AUTOSAR XML (schema 4-0-3)
standard types defined: uint8, Boolean, UInt16, UInt32, UInt8
package /AUTOSAR_Platform/DataConstrs
  range DC_Boolean: raw 0..1
  range DC_UInt16: raw 0..65535
  range DC_UInt8: raw 0..255
package /PATAC/Facility/DataTypes/Implementation
  compu method COMPU_Boolean: 0=FALSE, 1=TRUE
  unit NoUnit: factor-si-to-unit=1, offset-si-to-unit=0
package /PATAC/MSM/ComponentTypes
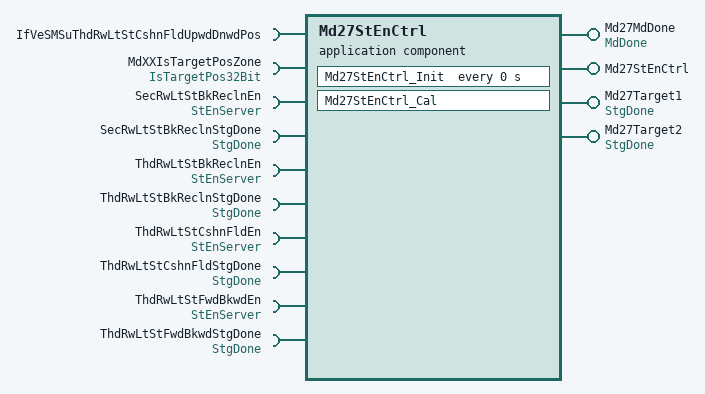
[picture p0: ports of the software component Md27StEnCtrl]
  application sw component type Md27StEnCtrl
    4 x provide port:
      Md27MdDone: nonqueued-sender-com-spec{data-element=MdDone/Val, init-value=0}, provided-interface=MdDone
      Md27StEnCtrl: server-com-spec{operation=Cal, queue-length=1}, provided-interface=Md27StEnCtrl
      Md27Target1: nonqueued-sender-com-spec{data-element=StgDone/Val, init-value=0}, provided-interface=StgDone
      Md27Target2: nonqueued-sender-com-spec{data-element=StgDone/Val, init-value=0}, provided-interface=StgDone
    10 x require port:
      IfVeSMSuThdRwLtStCshnFldUpwdDnwdPos: nonqueued-receiver-com-spec{data-element=IfVeSMSuThdRwLtStCshnFldUpwdDnwdPos/Val, filter=data-filter-type=ALWAYS, init-value=0}, required-interface=IfVeSMSuThdRwLtStCshnFldUpwdDnwdPos
      MdXXIsTargetPosZone: nonqueued-receiver-com-spec{data-element=IsTargetPos32Bit/Val, filter=data-filter-type=ALWAYS, init-value=0}, required-interface=IsTargetPos32Bit
      SecRwLtStBkReclnEn: required-com-specs=[Clear, Get, Set], required-interface=StEnServer
      SecRwLtStBkReclnStgDone: nonqueued-receiver-com-spec{data-element=StgDone/Val, filter=data-filter-type=ALWAYS, init-value=0}, required-interface=StgDone
      ThdRwLtStBkReclnEn: required-com-specs=[Clear, Get, Set], required-interface=StEnServer
      ThdRwLtStBkReclnStgDone: nonqueued-receiver-com-spec{data-element=StgDone/Val, filter=data-filter-type=ALWAYS, init-value=0}, required-interface=StgDone
      ThdRwLtStCshnFldEn: required-com-specs=[Clear, Get, Set], required-interface=StEnServer
      ThdRwLtStCshnFldStgDone: nonqueued-receiver-com-spec{data-element=StgDone/Val, filter=data-filter-type=ALWAYS, init-value=0}, required-interface=StgDone
      ThdRwLtStFwdBkwdEn: required-com-specs=[Clear, Get, Set], required-interface=StEnServer
      ThdRwLtStFwdBkwdStgDone: nonqueued-receiver-com-spec{data-element=StgDone/Val, filter=data-filter-type=ALWAYS, init-value=0}, required-interface=StgDone
    behavior Md27StEnCtrl_InternalBehavior
      operation invoked event OIT_Md27StEnCtrl_Cal_Md27StEnCtrl_Cal: start-on-event=Md27StEnCtrl_Cal, operation=Md27StEnCtrl.Cal
      timing event Md27StEnCtrl_InitEvent: start-on-event=Md27StEnCtrl_Init, period=0
      runnable Md27StEnCtrl_Cal
        data-receive-point-by-arguments:
          6 x access:
            REC_IfVeSMSuThdRwLtStCshnFldUpwdDnwdPos_Val: accessed-variable=IfVeSMSuThdRwLtStCshnFldUpwdDnwdPos.Val
            REC_MdXXIsTargetPosZone_Val: accessed-variable=MdXXIsTargetPosZone.Val
            REC_SecRwLtStBkReclnStgDone_Val: accessed-variable=SecRwLtStBkReclnStgDone.Val
            REC_ThdRwLtStBkReclnStgDone_Val: accessed-variable=ThdRwLtStBkReclnStgDone.Val
            REC_ThdRwLtStCshnFldStgDone_Val: accessed-variable=ThdRwLtStCshnFldStgDone.Val
            REC_ThdRwLtStFwdBkwdStgDone_Val: accessed-variable=ThdRwLtStFwdBkwdStgDone.Val
        data-send-points:
          access SEND_Md27MdDone_Val: accessed-variable=Md27MdDone.Val
          access SEND_Md27Target1_Val: accessed-variable=Md27Target1.Val
          access SEND_Md27Target2_Val: accessed-variable=Md27Target2.Val
        8 x sync call, all with timeout=0:
          SC_SecRwLtStBkReclnEn_Clear: operation=SecRwLtStBkReclnEn.Clear
          SC_SecRwLtStBkReclnEn_Set: operation=SecRwLtStBkReclnEn.Set
          SC_ThdRwLtStBkReclnEn_Clear: operation=ThdRwLtStBkReclnEn.Clear
          SC_ThdRwLtStBkReclnEn_Set: operation=ThdRwLtStBkReclnEn.Set
          SC_ThdRwLtStCshnFldEn_Clear: operation=ThdRwLtStCshnFldEn.Clear
          SC_ThdRwLtStCshnFldEn_Set: operation=ThdRwLtStCshnFldEn.Set
          SC_ThdRwLtStFwdBkwdEn_Clear: operation=ThdRwLtStFwdBkwdEn.Clear
          SC_ThdRwLtStFwdBkwdEn_Set: operation=ThdRwLtStFwdBkwdEn.Set
      runnable Md27StEnCtrl_Init
  swc implementation Md27StEnCtrl_Implementation: behavior=Md27StEnCtrl_InternalBehavior
    code-descriptors:
      code Default: artifact-descriptors=autosar-engineering-object={short-label=Default, category=SWSRC}
package /PATAC/MSM/ModeAdjust/Interfaces
  sender receiver interface IfVeSMSuThdRwLtStCshnFldUpwdDnwdPos: invalidation-policy{data-element=IfVeSMSuThdRwLtStCshnFldUpwdDnwdPos/Val, handle-invalid=DONT-INVALIDATE}
    data Val: type=UInt16
package /PATAC/MSM/ModeAdjust/PortInterface
  client server interface Md27StEnCtrl
    operation Cal
  client server interface StEnServer
    operation Clear
      arg data: type=UInt8, direction=IN, server-argument-impl-policy=USE-ARGUMENT-TYPE
    operation Get
      arg data: type=UInt32, direction=OUT, server-argument-impl-policy=USE-ARGUMENT-TYPE
    operation Set
      arg data: type=UInt8, direction=IN, server-argument-impl-policy=USE-ARGUMENT-TYPE
  sender receiver interface IsTargetPos32Bit: invalidation-policy{data-element=IsTargetPos32Bit/Val, handle-invalid=DONT-INVALIDATE}
    data Val: type=UInt32
  sender receiver interface MdDone: invalidation-policy{data-element=MdDone/Val, handle-invalid=DONT-INVALIDATE}
    data Val: type=UInt8
  sender receiver interface StgDone: invalidation-policy{data-element=StgDone/Val, handle-invalid=DONT-INVALIDATE}
    data Val: type=Boolean
